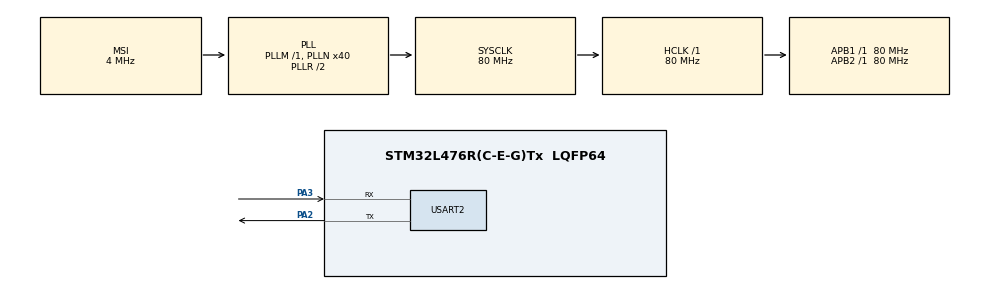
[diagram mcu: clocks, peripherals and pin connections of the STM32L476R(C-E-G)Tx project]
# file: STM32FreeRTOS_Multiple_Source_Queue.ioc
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FREERTOS.Queues01=myQueue,3,Data_t,0,Dynamic,NULL,NULL
FREERTOS.Tasks01=senderTask1,0,128,StartSenderTask,Default,NULL,Dynamic,NULL,NULL;senderTask2,0,128,StartSenderTask,Default,NULL,Dynamic,NULL,NULL;receiverTask,-1,128,StartReceiverTask,Default,NULL,Dynamic,NULL,NULL
FREERTOS.configUSE_NEWLIB_REENTRANT=1
Mcu.Family=STM32L4
Mcu.Name=STM32L476R(C-E-G)Tx
Mcu.Package=LQFP64
NVIC.PriorityGroup=NVIC_PRIORITYGROUP_4
NVIC.TIM1_UP_TIM16_IRQn=true\:15\:0\:false\:false\:true\:false\:false\:true\:true
NVIC.TimeBase=TIM1_UP_TIM16_IRQn
NVIC.TimeBaseIP=TIM1
PA13\ (JTMS-SWDIO).Mode=Serial_Wire
PA13\ (JTMS-SWDIO).Signal=SYS_JTMS-SWDIO
PA14\ (JTCK-SWCLK).Mode=Serial_Wire
PA14\ (JTCK-SWCLK).Signal=SYS_JTCK-SWCLK
PA2.Mode=Asynchronous
PA2.Signal=USART2_TX
PA3.Mode=Asynchronous
PA3.Signal=USART2_RX
PH0-OSC_IN\ (PH0).Mode=HSE-External-Oscillator
PH0-OSC_IN\ (PH0).Signal=RCC_OSC_IN
PH1-OSC_OUT\ (PH1).Mode=HSE-External-Oscillator
PH1-OSC_OUT\ (PH1).Signal=RCC_OSC_OUT
ProjectManager.HeapSize=0x200
ProjectManager.StackSize=0x400
ProjectManager.TargetToolchain=STM32CubeIDE
RCC.AHBFreq_Value=80000000
RCC.APB1Freq_Value=80000000
RCC.APB1TimFreq_Value=80000000
RCC.APB2Freq_Value=80000000
RCC.APB2TimFreq_Value=80000000
RCC.CortexFreq_Value=80000000
RCC.HCLKFreq_Value=80000000
RCC.HSE_VALUE=8000000
RCC.HSI_VALUE=16000000
RCC.LSE_VALUE=32768
RCC.MSI_VALUE=4000000
RCC.PLLN=40
RCC.SYSCLKFreq_VALUE=80000000
RCC.SYSCLKSource=RCC_SYSCLKSOURCE_PLLCLK
RCC.VCOOutputFreq_Value=160000000
USART2.VirtualMode-Asynchronous=VM_ASYNC
VP_FREERTOS_VS_CMSIS_V1.Mode=CMSIS_V1
VP_SYS_VS_tim1.Mode=TIM1
board=custom

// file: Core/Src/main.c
/* USER CODE BEGIN Header */
/**
  ******************************************************************************
  * @file           : main.c
  * @brief          : Main program body
  ******************************************************************************
  * @attention
  *
  * Copyright (c) 2024 STMicroelectronics.
  * All rights reserved.
  *
  * This software is licensed under terms that can be found in the LICENSE file
  * in the root directory of this software component.
  * If no LICENSE file comes with this software, it is provided AS-IS.
  *
  ******************************************************************************
  */
/* USER CODE END Header */
#include "main.h"
#include "cmsis_os.h"

/* USER CODE BEGIN Includes */
#include "SEGGER_SYSVIEW.h"
#include <string.h>
#include <inttypes.h>
#include <stdio.h>
/* USER CODE END Includes */

UART_HandleTypeDef huart2;

osThreadId senderTask1Handle;
osThreadId senderTask2Handle;
osThreadId receiverTaskHandle;
osMessageQId myQueueHandle;

void SystemClock_Config(void);
static void MX_GPIO_Init(void);
static void MX_USART2_UART_Init(void);
void StartSenderTask(void const * argument);
void StartReceiverTask(void const * argument);

/* USER CODE BEGIN PFP */
void printTaskText(const uint8_t * argument);
/* USER CODE END PFP */

/* USER CODE BEGIN 0 */
typedef enum
{
 eSender1,
 eSender2
} DataSource_t;

/* The structure type that will be passed on the queue. */
typedef struct
{
 uint8_t ucValue;
 DataSource_t eDataSource;
} Data_t;

/* Two variables of type Data_t that will be passed on the queue. */
static const Data_t xStructsToSend[ 2 ] =
{
 { 100, eSender1 }, /* Used by Sender1. */
 { 200, eSender2 } /* Used by Sender2. */
};

/* USER CODE END 0 */

int main(void)
{

  /* MCU Configuration--------------------------------------------------------*/

  /* Reset of all peripherals, Initializes the Flash interface and the Systick. */
  HAL_Init();

  /* Configure the system clock */
  SystemClock_Config();

  /* Initialize all configured peripherals */
  MX_GPIO_Init();
  MX_USART2_UART_Init();
  /* USER CODE BEGIN 2 */
  SEGGER_SYSVIEW_Conf();
  vSetVarulMaxPRIGROUPValue();
  SEGGER_SYSVIEW_Start();
  /* USER CODE END 2 */

  /* Create the queue(s) */
  /* definition and creation of myQueue */
  osMessageQDef(myQueue, 3, Data_t);
  myQueueHandle = osMessageCreate(osMessageQ(myQueue), NULL);

  /* Create the thread(s) */
  /* definition and creation of senderTask1 */
  osThreadDef(senderTask1, StartSenderTask, osPriorityNormal, 0, 128);
  senderTask1Handle = osThreadCreate(osThread(senderTask1), (void *)&(xStructsToSend[0]));

  /* definition and creation of senderTask2 */
  osThreadDef(senderTask2, StartSenderTask, osPriorityNormal, 0, 128);
  senderTask2Handle = osThreadCreate(osThread(senderTask2), (void *)&(xStructsToSend[1]));

  /* definition and creation of receiverTask */
  osThreadDef(receiverTask, StartReceiverTask, osPriorityBelowNormal, 0, 128);
  receiverTaskHandle = osThreadCreate(osThread(receiverTask), NULL);

  /* Start scheduler */
  osKernelStart();

  /* We should never get here as control is now taken by the scheduler */
  /* Infinite loop */
  while (1)
  {

  }
}

void SystemClock_Config(void)
{
  RCC_OscInitTypeDef RCC_OscInitStruct = {0};
  RCC_ClkInitTypeDef RCC_ClkInitStruct = {0};

  /** Configure the main internal regulator output voltage
  */
  if (HAL_PWREx_ControlVoltageScaling(PWR_REGULATOR_VOLTAGE_SCALE1) != HAL_OK)
  {
    Error_Handler();
  }

  /** Initializes the RCC Oscillators according to the specified parameters
  * in the RCC_OscInitTypeDef structure.
  */
  RCC_OscInitStruct.OscillatorType = RCC_OSCILLATORTYPE_MSI;
  RCC_OscInitStruct.MSIState = RCC_MSI_ON;
  RCC_OscInitStruct.MSICalibrationValue = 0;
  RCC_OscInitStruct.MSIClockRange = RCC_MSIRANGE_6;
  RCC_OscInitStruct.PLL.PLLState = RCC_PLL_ON;
  RCC_OscInitStruct.PLL.PLLSource = RCC_PLLSOURCE_MSI;
  RCC_OscInitStruct.PLL.PLLM = 1;
  RCC_OscInitStruct.PLL.PLLN = 40;
  RCC_OscInitStruct.PLL.PLLP = RCC_PLLP_DIV7;
  RCC_OscInitStruct.PLL.PLLQ = RCC_PLLQ_DIV2;
  RCC_OscInitStruct.PLL.PLLR = RCC_PLLR_DIV2;
  if (HAL_RCC_OscConfig(&RCC_OscInitStruct) != HAL_OK)
  {
    Error_Handler();
  }

  /** Initializes the CPU, AHB and APB buses clocks
  */
  RCC_ClkInitStruct.ClockType = RCC_CLOCKTYPE_HCLK|RCC_CLOCKTYPE_SYSCLK
                              |RCC_CLOCKTYPE_PCLK1|RCC_CLOCKTYPE_PCLK2;
  RCC_ClkInitStruct.SYSCLKSource = RCC_SYSCLKSOURCE_PLLCLK;
  RCC_ClkInitStruct.AHBCLKDivider = RCC_SYSCLK_DIV1;
  RCC_ClkInitStruct.APB1CLKDivider = RCC_HCLK_DIV1;
  RCC_ClkInitStruct.APB2CLKDivider = RCC_HCLK_DIV1;

  if (HAL_RCC_ClockConfig(&RCC_ClkInitStruct, FLASH_LATENCY_4) != HAL_OK)
  {
    Error_Handler();
  }
}

static void MX_USART2_UART_Init(void)
{

  huart2.Instance = USART2;
  huart2.Init.BaudRate = 115200;
  huart2.Init.WordLength = UART_WORDLENGTH_8B;
  huart2.Init.StopBits = UART_STOPBITS_1;
  huart2.Init.Parity = UART_PARITY_NONE;
  huart2.Init.Mode = UART_MODE_TX_RX;
  huart2.Init.HwFlowCtl = UART_HWCONTROL_NONE;
  huart2.Init.OverSampling = UART_OVERSAMPLING_16;
  huart2.Init.OneBitSampling = UART_ONE_BIT_SAMPLE_DISABLE;
  huart2.AdvancedInit.AdvFeatureInit = UART_ADVFEATURE_NO_INIT;
  if (HAL_UART_Init(&huart2) != HAL_OK)
  {
    Error_Handler();
  }

}

static void MX_GPIO_Init(void)
{

  /* GPIO Ports Clock Enable */
  __HAL_RCC_GPIOH_CLK_ENABLE();
  __HAL_RCC_GPIOA_CLK_ENABLE();

}

/* USER CODE BEGIN 4 */
void printTaskText(const uint8_t * argument){
	HAL_UART_Transmit(&huart2,  argument, strlen((char *)argument), 5);
}
/* USER CODE END 4 */

void StartSenderTask(const void * argument)
{
  /* USER CODE BEGIN 5 */
	BaseType_t xStatus;
	const TickType_t xTicksToWait = pdMS_TO_TICKS( 100 );
  /* Infinite loop */
  for(;;){
	  xStatus = xQueueSendToBack( myQueueHandle, argument, xTicksToWait );
	   if( xStatus != pdPASS ){
	   /* The send operation could not complete, even after waiting for 100ms.
	   This must be an error as the receiving task should make space in the
	   queue as soon as both sending tasks are in the Blocked state. */
		   printTaskText(( uint8_t *)"Could not send to the queue.\r\n" );
	   }

  }
  /* USER CODE END 5 */
}

void StartReceiverTask(void const * argument)
{
  /* USER CODE BEGIN StartReceiverTask */
	Data_t xReceivedStructure;
	BaseType_t xStatus;
	char text[100];
  /* Infinite loop */
  for(;;){
	  /* Because it has the lowest priority this task will only run when the
	   sending tasks are in the Blocked state. The sending tasks will only enter
	   the Blocked state when the queue is full so this task always expects the
	   number of items in the queue to be equal to the queue length, which is 3 in
	   this case. */
	   if( uxQueueMessagesWaiting( myQueueHandle ) != 3 ){
		   printTaskText(( uint8_t *) "Queue should have been full!\r\n" );
	   }
	   /* Receive from the queue.
	   The second parameter is the buffer into which the received data will be
	   placed. In this case the buffer is simply the address of a variable that
	   has the required size to hold the received structure.
	   The last parameter is the block time - the maximum amount of time that the
	   task will remain in the Blocked state to wait for data to be available
	   if the queue is already empty. In this case a block time is not necessary
	   because this task will only run when the queue is full. */
	   xStatus = xQueueReceive( myQueueHandle, &xReceivedStructure, 0 );
	   if( xStatus == pdPASS ){
		   /* Data was successfully received from the queue, print out the received
		   value and the source of the value. */
		   if( xReceivedStructure.eDataSource == eSender1 ){
 				 sprintf(text, "From Sender 1 =  %u \r\n", xReceivedStructure.ucValue);
				 printTaskText((const uint8_t *)text);
		   }else{
				sprintf(text, "From Sender 2 =  %u \r\n", xReceivedStructure.ucValue);
				printTaskText((const uint8_t *)text);
 		   }
	   }
	   else{
	   /* Nothing was received from the queue. This must be an error as this
	   task should only run when the queue is full. */
		   printTaskText(( uint8_t *) "Could not receive from the queue.\r\n" );
	   }
  }
  /* USER CODE END StartReceiverTask */
}

void HAL_TIM_PeriodElapsedCallback(TIM_HandleTypeDef *htim)
{
  if (htim->Instance == TIM1) {
    HAL_IncTick();
  }
}

void Error_Handler(void)
{
  __disable_irq();
  while (1)
  {
  }
}
